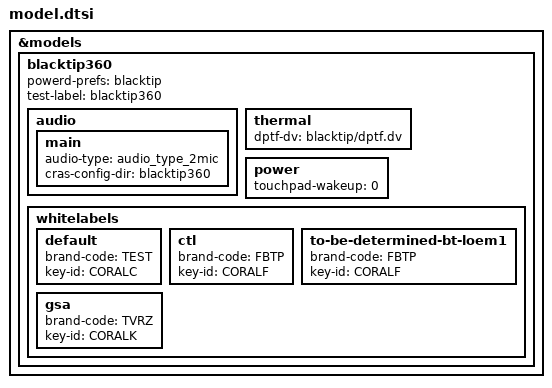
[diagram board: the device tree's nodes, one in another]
/*
 * Copyright 2017 The Chromium OS Authors. All rights reserved.
 *
 * Use of this source code is governed by a BSD-style license that can be
 * found in the LICENSE file.
 */

&models {
	blacktip360: blacktip360 {
		powerd-prefs = "blacktip";
		test-label = "blacktip360";
		audio {
			main {
				audio-type = <&audio_type_2mic>;
				cras-config-dir = "blacktip360";
			};
		};
		thermal {
			/* Could also point to astronaut/dptf.dv */
			dptf-dv = "blacktip/dptf.dv";
		};
		power {
			touchpad-wakeup = "0";
		};
		whitelabels {
			// *default* LOEM
			default {
				brand-code = "TEST";
				key-id = "CORALC";
			};
			ctl {
				brand-code = "FBTP";
				key-id = "CORALF";
			};
			// Workaround to make it compatible with "ctl"
			to-be-determined-bt-loem1 {
				brand-code = "FBTP";
				key-id = "CORALF";
			};
			gsa {
				brand-code = "TVRZ";
				key-id = "CORALK";
			};
		};
	};
};
